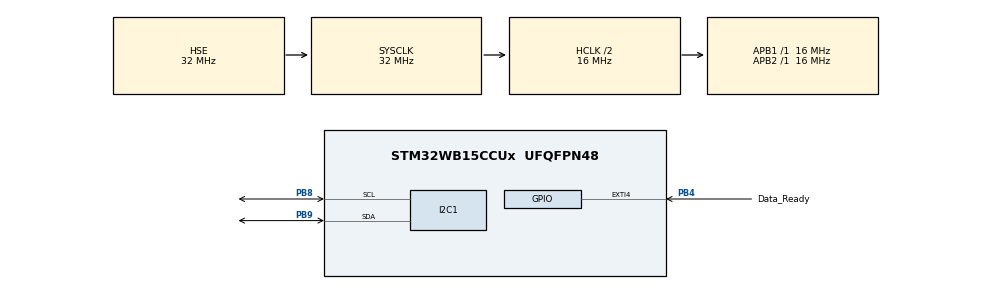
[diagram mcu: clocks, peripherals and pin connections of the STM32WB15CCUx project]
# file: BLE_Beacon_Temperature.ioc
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I2C1.Timing=0x00303D5B
Mcu.Family=STM32WB
Mcu.Name=STM32WB15CCUx
Mcu.Package=UFQFPN48
NVIC.EXTI4_IRQn=true\:0\:0\:false\:false\:true\:true\:true\:true
NVIC.HSEM_IRQn=true\:0\:0\:false\:false\:true\:false\:true\:true
NVIC.IPCC_C1_RX_IRQn=true\:0\:0\:false\:false\:true\:true\:true\:true
NVIC.IPCC_C1_TX_IRQn=true\:0\:0\:false\:false\:true\:true\:true\:true
NVIC.PriorityGroup=NVIC_PRIORITYGROUP_4
NVIC.RTC_WKUP_IRQn=true\:15\:0\:true\:false\:true\:true\:true\:true
OSC_IN.Mode=HSE-External-Oscillator
OSC_IN.Signal=RCC_OSC_IN
OSC_OUT.Mode=HSE-External-Oscillator
OSC_OUT.Signal=RCC_OSC_OUT
PB4.GPIO_Label=Data_Ready
PB4.GPIO_ModeDefaultEXTI=GPIO_MODE_IT_FALLING
PB4.Signal=GPXTI4
PB8.Mode=I2C
PB8.Signal=I2C1_SCL
PB9.Mode=I2C
PB9.Signal=I2C1_SDA
PC14-OSC32_IN.Mode=LSE-External-Oscillator
PC14-OSC32_IN.Signal=RCC_OSC32_IN
PC15-OSC32_OUT.Mode=LSE-External-Oscillator
PC15-OSC32_OUT.Signal=RCC_OSC32_OUT
ProjectManager.HeapSize=0x200
ProjectManager.StackSize=0x400
ProjectManager.TargetToolchain=STM32CubeIDE
RCC.AHBCLKDivider=RCC_SYSCLK_DIV2
RCC.AHBFreq_Value=16000000
RCC.APB1Freq_Value=16000000
RCC.APB1TimFreq_Value=16000000
RCC.APB2Freq_Value=16000000
RCC.APB2TimFreq_Value=16000000
RCC.APB3Freq_Value=16000000
RCC.CortexFreq_Value=16000000
RCC.HCLKFreq_Value=16000000
RCC.HSE_VALUE=32000000
RCC.HSI_VALUE=16000000
RCC.LSE_Drive_Capability=RCC_LSEDRIVE_LOW
RCC.RFWKPClockSelection=RCC_RFWKPCLKSOURCE_LSE
RCC.RTCClockSelection=RCC_RTCCLKSOURCE_LSE
RCC.SYSCLKFreq_VALUE=32000000
RCC.SYSCLKSource=RCC_SYSCLKSOURCE_HSE
RCC.VCOOutputFreq_Value=32000000
RF1.Mode=RF1_Activate
RF1.Signal=RF_RF1
RTC.WakeUpCounter-WakeUp=0xFFFF
STM32_WPAN.BT_SIG_BEACON=CFG_IBEACON
STM32_WPAN.CFG_BLE_ATT_VALUE_ARRAY_SIZE=1290
STM32_WPAN.CFG_BLE_DATA_LENGTH_EXTENSION=0
STM32_WPAN.CFG_BLE_NUM_GATT_ATTRIBUTES=30
STM32_WPAN.CFG_BLE_NUM_GATT_SERVICES=4
STM32_WPAN.CFG_DEBUGGER_SUPPORTED=0
STM32_WPAN.CFG_IO_CAPABILITY=\ CFG_IO_CAPABILITY_NO_INPUT_NO_OUTPUT
STM32_WPAN.CFG_LPM_SUPPORTED=1
STM32_WPAN.CFG_TX_POWER=(0x19) /* 0dBm */
STM32_WPAN.CFG_USE_SMPS=1
STM32_WPAN.DBG_TRACE_USE_CIRCULAR_QUEUE=0
VP_HSEM_VS_HSEM.Mode=HSEM_Activate
VP_IPCC_VS_IPCC.Mode=IPCC_Activate
VP_RTC_VS_RTC_Activate.Mode=RTC_Enabled
VP_RTC_VS_RTC_WakeUp_intern.Mode=WakeUp
VP_SEQUENCER_VS_SEQUENCER.Mode=SEQUENCER_Enabled
VP_STM32_WPAN_VS_BLE_HOST.Mode=STM32_WPAN_Enabled
VP_TINY_LPM_VS_TINY_LPM.Mode=TINY_LPM_Enabled
board=custom

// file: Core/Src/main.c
/* USER CODE BEGIN Header */
/**
  ******************************************************************************
  * @file           : main.c
  * @brief          : Main program body
  ******************************************************************************
  * @attention
  *
  * Copyright (c) 2023 STMicroelectronics.
  * All rights reserved.
  *
  * This software is licensed under terms that can be found in the LICENSE file
  * in the root directory of this software component.
  * If no LICENSE file comes with this software, it is provided AS-IS.
  *
  ******************************************************************************
  */
/* USER CODE END Header */
#include "main.h"

/* USER CODE BEGIN Includes */
#include <stdio.h>
#include "stm32_seq.h"
/* USER CODE END Includes */

I2C_HandleTypeDef hi2c1;

IPCC_HandleTypeDef hipcc;

RTC_HandleTypeDef hrtc;

/* USER CODE BEGIN PV */
uint16_t temperature_val = 0;
/* USER CODE END PV */

void SystemClock_Config(void);
void PeriphCommonClock_Config(void);
static void MX_GPIO_Init(void);
static void MX_I2C1_Init(void);
static void MX_IPCC_Init(void);
static void MX_RTC_Init(void);
static void MX_RF_Init(void);

int main(void)
{

  /* MCU Configuration--------------------------------------------------------*/

  /* Reset of all peripherals, Initializes the Flash interface and the Systick. */
  HAL_Init();
  /* Config code for STM32_WPAN (HSE Tuning must be done before system clock configuration) */
  MX_APPE_Config();

  /* Configure the system clock */
  SystemClock_Config();

/* Configure the peripherals common clocks */
  PeriphCommonClock_Config();

  /* IPCC initialisation */
  MX_IPCC_Init();

  /* Initialize all configured peripherals */
  MX_GPIO_Init();
  MX_I2C1_Init();
  MX_RTC_Init();
  MX_RF_Init();

  /* Init code for STM32_WPAN */
  MX_APPE_Init();

  /* Infinite loop */
  while (1)
  {
    MX_APPE_Process();

  }
}

void SystemClock_Config(void)
{
  RCC_OscInitTypeDef RCC_OscInitStruct = {0};
  RCC_ClkInitTypeDef RCC_ClkInitStruct = {0};

  /** Configure LSE Drive Capability
  */
  HAL_PWR_EnableBkUpAccess();
  __HAL_RCC_LSEDRIVE_CONFIG(RCC_LSEDRIVE_LOW);

  /** Initializes the RCC Oscillators according to the specified parameters
  * in the RCC_OscInitTypeDef structure.
  */
  RCC_OscInitStruct.OscillatorType = RCC_OSCILLATORTYPE_HSI|RCC_OSCILLATORTYPE_HSE
                              |RCC_OSCILLATORTYPE_LSE;
  RCC_OscInitStruct.HSEState = RCC_HSE_ON;
  RCC_OscInitStruct.LSEState = RCC_LSE_ON;
  RCC_OscInitStruct.HSIState = RCC_HSI_ON;
  RCC_OscInitStruct.HSICalibrationValue = RCC_HSICALIBRATION_DEFAULT;
  RCC_OscInitStruct.PLL.PLLState = RCC_PLL_NONE;
  if (HAL_RCC_OscConfig(&RCC_OscInitStruct) != HAL_OK)
  {
    Error_Handler();
  }

  /** Configure the SYSCLKSource, HCLK, PCLK1 and PCLK2 clocks dividers
  */
  RCC_ClkInitStruct.ClockType = RCC_CLOCKTYPE_HCLK4|RCC_CLOCKTYPE_HCLK2
                              |RCC_CLOCKTYPE_HCLK|RCC_CLOCKTYPE_SYSCLK
                              |RCC_CLOCKTYPE_PCLK1|RCC_CLOCKTYPE_PCLK2;
  RCC_ClkInitStruct.SYSCLKSource = RCC_SYSCLKSOURCE_HSE;
  RCC_ClkInitStruct.AHBCLKDivider = RCC_SYSCLK_DIV2;
  RCC_ClkInitStruct.APB1CLKDivider = RCC_HCLK_DIV1;
  RCC_ClkInitStruct.APB2CLKDivider = RCC_HCLK_DIV1;
  RCC_ClkInitStruct.AHBCLK2Divider = RCC_SYSCLK_DIV1;
  RCC_ClkInitStruct.AHBCLK4Divider = RCC_SYSCLK_DIV1;

  if (HAL_RCC_ClockConfig(&RCC_ClkInitStruct, FLASH_LATENCY_1) != HAL_OK)
  {
    Error_Handler();
  }
}

void PeriphCommonClock_Config(void)
{
  RCC_PeriphCLKInitTypeDef PeriphClkInitStruct = {0};

  /** Initializes the peripherals clock
  */
  PeriphClkInitStruct.PeriphClockSelection = RCC_PERIPHCLK_SMPS|RCC_PERIPHCLK_RFWAKEUP;
  PeriphClkInitStruct.RFWakeUpClockSelection = RCC_RFWKPCLKSOURCE_LSE;
  PeriphClkInitStruct.SmpsClockSelection = RCC_SMPSCLKSOURCE_HSI;
  PeriphClkInitStruct.SmpsDivSelection = RCC_SMPSCLKDIV_RANGE1;

  if (HAL_RCCEx_PeriphCLKConfig(&PeriphClkInitStruct) != HAL_OK)
  {
    Error_Handler();
  }
}

static void MX_I2C1_Init(void)
{

  hi2c1.Instance = I2C1;
  hi2c1.Init.Timing = 0x00303D5B;
  hi2c1.Init.OwnAddress1 = 0;
  hi2c1.Init.AddressingMode = I2C_ADDRESSINGMODE_7BIT;
  hi2c1.Init.DualAddressMode = I2C_DUALADDRESS_DISABLE;
  hi2c1.Init.OwnAddress2 = 0;
  hi2c1.Init.OwnAddress2Masks = I2C_OA2_NOMASK;
  hi2c1.Init.GeneralCallMode = I2C_GENERALCALL_DISABLE;
  hi2c1.Init.NoStretchMode = I2C_NOSTRETCH_DISABLE;
  if (HAL_I2C_Init(&hi2c1) != HAL_OK)
  {
    Error_Handler();
  }

  /** Configure Analogue filter
  */
  if (HAL_I2CEx_ConfigAnalogFilter(&hi2c1, I2C_ANALOGFILTER_ENABLE) != HAL_OK)
  {
    Error_Handler();
  }

  /** Configure Digital filter
  */
  if (HAL_I2CEx_ConfigDigitalFilter(&hi2c1, 0) != HAL_OK)
  {
    Error_Handler();
  }

}

static void MX_IPCC_Init(void)
{

  hipcc.Instance = IPCC;
  if (HAL_IPCC_Init(&hipcc) != HAL_OK)
  {
    Error_Handler();
  }

}

static void MX_RF_Init(void)
{

}

static void MX_RTC_Init(void)
{

  /** Initialize RTC Only
  */
  hrtc.Instance = RTC;
  hrtc.Init.HourFormat = RTC_HOURFORMAT_24;
  hrtc.Init.AsynchPrediv = CFG_RTC_ASYNCH_PRESCALER;
  hrtc.Init.SynchPrediv = CFG_RTC_SYNCH_PRESCALER;
  hrtc.Init.OutPut = RTC_OUTPUT_DISABLE;
  hrtc.Init.OutPutPolarity = RTC_OUTPUT_POLARITY_HIGH;
  hrtc.Init.OutPutRemap = RTC_OUTPUT_REMAP_NONE;
  if (HAL_RTC_Init(&hrtc) != HAL_OK)
  {
    Error_Handler();
  }

  /** Enable the WakeUp
  */
  if (HAL_RTCEx_SetWakeUpTimer_IT(&hrtc, 0xFFFF, RTC_WAKEUPCLOCK_RTCCLK_DIV16) != HAL_OK)
  {
    Error_Handler();
  }
  /* USER CODE BEGIN RTC_Init 2 */
  HAL_RTCEx_DeactivateWakeUpTimer(&hrtc);
  /* USER CODE END RTC_Init 2 */

}

static void MX_GPIO_Init(void)
{
  GPIO_InitTypeDef GPIO_InitStruct = {0};

  /* GPIO Ports Clock Enable */
  __HAL_RCC_GPIOC_CLK_ENABLE();
  __HAL_RCC_GPIOH_CLK_ENABLE();
  __HAL_RCC_GPIOB_CLK_ENABLE();
  __HAL_RCC_GPIOA_CLK_ENABLE();
  __HAL_RCC_GPIOE_CLK_ENABLE();

  /*Configure GPIO pin : PH3 */
  GPIO_InitStruct.Pin = GPIO_PIN_3;
  GPIO_InitStruct.Mode = GPIO_MODE_ANALOG;
  GPIO_InitStruct.Pull = GPIO_NOPULL;
  HAL_GPIO_Init(GPIOH, &GPIO_InitStruct);

  /*Configure GPIO pins : PA0 PA1 PA2 PA3
                           PA4 PA5 PA6 PA7
                           PA8 PA9 PA10 PA11
                           PA12 PA13 PA14 PA15 */
  GPIO_InitStruct.Pin = GPIO_PIN_0|GPIO_PIN_1|GPIO_PIN_2|GPIO_PIN_3
                          |GPIO_PIN_4|GPIO_PIN_5|GPIO_PIN_6|GPIO_PIN_7
                          |GPIO_PIN_8|GPIO_PIN_9|GPIO_PIN_10|GPIO_PIN_11
                          |GPIO_PIN_12|GPIO_PIN_13|GPIO_PIN_14|GPIO_PIN_15;
  GPIO_InitStruct.Mode = GPIO_MODE_ANALOG;
  GPIO_InitStruct.Pull = GPIO_NOPULL;
  HAL_GPIO_Init(GPIOA, &GPIO_InitStruct);

  /*Configure GPIO pins : PB2 PB0 PB1 PB3
                           PB5 PB6 PB7 */
  GPIO_InitStruct.Pin = GPIO_PIN_2|GPIO_PIN_0|GPIO_PIN_1|GPIO_PIN_3
                          |GPIO_PIN_5|GPIO_PIN_6|GPIO_PIN_7;
  GPIO_InitStruct.Mode = GPIO_MODE_ANALOG;
  GPIO_InitStruct.Pull = GPIO_NOPULL;
  HAL_GPIO_Init(GPIOB, &GPIO_InitStruct);

  /*Configure GPIO pin : PE4 */
  GPIO_InitStruct.Pin = GPIO_PIN_4;
  GPIO_InitStruct.Mode = GPIO_MODE_ANALOG;
  GPIO_InitStruct.Pull = GPIO_NOPULL;
  HAL_GPIO_Init(GPIOE, &GPIO_InitStruct);

  /*Configure GPIO pin : Data_Ready_Pin */
  GPIO_InitStruct.Pin = Data_Ready_Pin;
  GPIO_InitStruct.Mode = GPIO_MODE_IT_FALLING;
  GPIO_InitStruct.Pull = GPIO_NOPULL;
  HAL_GPIO_Init(Data_Ready_GPIO_Port, &GPIO_InitStruct);

  /* EXTI interrupt init*/
  HAL_NVIC_SetPriority(EXTI4_IRQn, 0, 0);
  HAL_NVIC_EnableIRQ(EXTI4_IRQn);

}

/* USER CODE BEGIN 4 */
void HAL_GPIO_EXTI_Callback(uint16_t GPIO_Pin) {
	if(GPIO_Pin == Data_Ready_Pin) {
		SystemClock_Config ();
		HAL_ResumeTick();
		UTIL_SEQ_SetTask(1<<CFG_TASK_UPDATE_TEMP, CFG_SCH_PRIO_0);
	}
}

//void HAL_RTCEx_WakeUpTimerEventCallback(RTC_HandleTypeDef *hrtc) {
//	SystemClock_Config ();
//	HAL_ResumeTick();
//	UTIL_SEQ_SetTask(1<<CFG_TASK_UPDATE_TEMP, CFG_SCH_PRIO_0);
//
//}
/* USER CODE END 4 */

void Error_Handler(void)
{
  __disable_irq();
  while (1)
  {
  }
}
